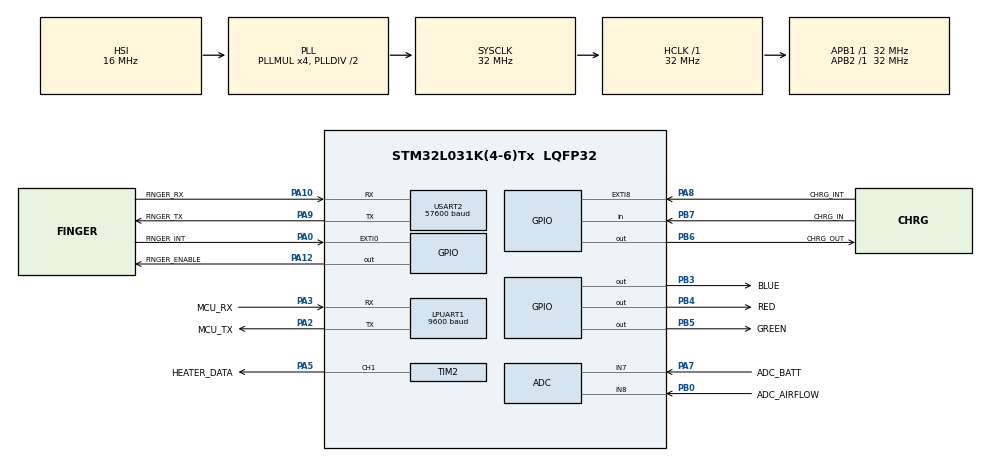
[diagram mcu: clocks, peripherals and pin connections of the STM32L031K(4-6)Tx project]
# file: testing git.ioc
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ADC.ContinuousConvMode=ENABLE
ADC.DMAContinuousRequests=ENABLE
ADC.SamplingTime=ADC_SAMPLETIME_160CYCLES_5
Dma.ADC.3.Direction=DMA_PERIPH_TO_MEMORY
Dma.ADC.3.Instance=DMA1_Channel1
Dma.ADC.3.MemDataAlignment=DMA_MDATAALIGN_WORD
Dma.ADC.3.MemInc=DMA_MINC_ENABLE
Dma.ADC.3.Mode=DMA_CIRCULAR
Dma.ADC.3.PeriphDataAlignment=DMA_PDATAALIGN_WORD
Dma.ADC.3.PeriphInc=DMA_PINC_DISABLE
Dma.ADC.3.Priority=DMA_PRIORITY_LOW
Dma.LPUART1_RX.1.Direction=DMA_PERIPH_TO_MEMORY
Dma.LPUART1_RX.1.Instance=DMA1_Channel3
Dma.LPUART1_RX.1.MemDataAlignment=DMA_MDATAALIGN_BYTE
Dma.LPUART1_RX.1.MemInc=DMA_MINC_ENABLE
Dma.LPUART1_RX.1.Mode=DMA_NORMAL
Dma.LPUART1_RX.1.PeriphDataAlignment=DMA_PDATAALIGN_BYTE
Dma.LPUART1_RX.1.PeriphInc=DMA_PINC_DISABLE
Dma.LPUART1_RX.1.Priority=DMA_PRIORITY_LOW
Dma.LPUART1_TX.2.Direction=DMA_MEMORY_TO_PERIPH
Dma.LPUART1_TX.2.Instance=DMA1_Channel2
Dma.LPUART1_TX.2.MemDataAlignment=DMA_MDATAALIGN_BYTE
Dma.LPUART1_TX.2.MemInc=DMA_MINC_ENABLE
Dma.LPUART1_TX.2.Mode=DMA_NORMAL
Dma.LPUART1_TX.2.PeriphDataAlignment=DMA_PDATAALIGN_BYTE
Dma.LPUART1_TX.2.PeriphInc=DMA_PINC_DISABLE
Dma.LPUART1_TX.2.Priority=DMA_PRIORITY_LOW
Dma.Request0=TIM2_CH1
Dma.Request1=LPUART1_RX
Dma.Request2=LPUART1_TX
Dma.Request3=ADC
Dma.TIM2_CH1.0.Direction=DMA_MEMORY_TO_PERIPH
Dma.TIM2_CH1.0.Instance=DMA1_Channel5
Dma.TIM2_CH1.0.MemDataAlignment=DMA_MDATAALIGN_HALFWORD
Dma.TIM2_CH1.0.MemInc=DMA_MINC_ENABLE
Dma.TIM2_CH1.0.Mode=DMA_CIRCULAR
Dma.TIM2_CH1.0.PeriphDataAlignment=DMA_PDATAALIGN_HALFWORD
Dma.TIM2_CH1.0.PeriphInc=DMA_PINC_DISABLE
Dma.TIM2_CH1.0.Priority=DMA_PRIORITY_HIGH
LPUART1.BaudRate=9600
LPUART1.WordLength=UART_WORDLENGTH_8B
Mcu.Family=STM32L0
Mcu.Name=STM32L031K(4-6)Tx
Mcu.Package=LQFP32
NVIC.ADC1_COMP_IRQn=true\:1\:0\:true\:false\:true\:true\:true\:true
NVIC.DMA1_Channel1_IRQn=true\:0\:0\:false\:false\:true\:false\:true\:true
NVIC.DMA1_Channel2_3_IRQn=true\:0\:0\:false\:false\:true\:false\:true\:true
NVIC.DMA1_Channel4_5_6_7_IRQn=true\:0\:0\:true\:false\:true\:false\:true\:true
NVIC.EXTI0_1_IRQn=true\:3\:0\:true\:false\:true\:true\:true\:true
NVIC.EXTI4_15_IRQn=true\:3\:0\:true\:false\:true\:true\:true\:true
NVIC.LPUART1_IRQn=true\:1\:0\:true\:false\:true\:true\:true\:true
NVIC.TIM2_IRQn=true\:1\:0\:true\:false\:true\:true\:true\:true
PA0-CK_IN.GPIO_Label=FINGER_INT
PA0-CK_IN.Signal=GPXTI0
PA10.GPIO_Label=FINGER_RX
PA10.Mode=Asynchronous
PA10.Signal=USART2_RX
PA12.GPIO_Label=FINGER_ENABLE
PA12.Signal=GPIO_Output
PA13.Mode=Serial_Wire
PA13.Signal=SYS_SWDIO
PA14.Mode=Serial_Wire
PA14.Signal=SYS_SWCLK
PA2.GPIO_Label=MCU_TX
PA2.Mode=Asynchronous
PA2.Signal=LPUART1_TX
PA3.GPIO_Label=MCU_RX
PA3.Mode=Asynchronous
PA3.Signal=LPUART1_RX
PA5.GPIO_Label=HEATER_DATA
PA5.GPIO_PuPd=GPIO_PULLDOWN
PA5.GPIO_Speed=GPIO_SPEED_FREQ_VERY_HIGH
PA5.Signal=S_TIM2_CH1
PA7.GPIO_Label=ADC_BATT
PA7.Mode=IN7
PA7.Signal=ADC_IN7
PA8.GPIO_Label=CHRG_INT
PA8.Signal=GPXTI8
PA9.GPIO_Label=FINGER_TX
PA9.Mode=Asynchronous
PA9.Signal=USART2_TX
PB0.GPIO_Label=ADC_AIRFLOW
PB0.Mode=IN8
PB0.Signal=ADC_IN8
PB3.GPIO_Label=BLUE
PB3.Signal=GPIO_Output
PB4.GPIO_Label=RED
PB4.Signal=GPIO_Output
PB5.GPIO_Label=GREEN
PB5.Signal=GPIO_Output
PB6.GPIO_Label=CHRG_OUT
PB6.Signal=GPIO_Output
PB7.GPIO_Label=CHRG_IN
PB7.Signal=GPIO_Input
ProjectManager.HeapSize=0x200
ProjectManager.StackSize=0x400
ProjectManager.TargetToolchain=STM32CubeIDE
RCC.ADCFreq_Value=16000000
RCC.AHBFreq_Value=32000000
RCC.APB1Freq_Value=32000000
RCC.APB1TimFreq_Value=32000000
RCC.APB2Freq_Value=32000000
RCC.APB2TimFreq_Value=32000000
RCC.HCLKFreq_Value=32000000
RCC.HSE_VALUE=8000000
RCC.HSI16_VALUE=16000000
RCC.HSI_VALUE=16000000
RCC.LSE_VALUE=32768
RCC.MSIClockRange=RCC_MSIRANGE_6
RCC.MSI_VALUE=4194000
RCC.PLLMUL=RCC_PLLMUL_4
RCC.SYSCLKFreq_VALUE=32000000
RCC.SYSCLKSource=RCC_SYSCLKSOURCE_PLLCLK
RCC.VCOOutputFreq_Value=64000000
SH.S_TIM2_CH1.0=TIM2_CH1,PWM Generation1 CH1
TIM2.Channel-PWM\ Generation1\ CH1=TIM_CHANNEL_1
TIM2.Period=40-1
USART2.BaudRate=57600
USART2.VirtualMode-Asynchronous=VM_ASYNC
VP_ADC_Vref_Input.Mode=IN-Vrefint
VP_TIM2_VS_ClockSourceINT.Mode=Internal
board=custom

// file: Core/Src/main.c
/* USER CODE BEGIN Header */
/**
  ******************************************************************************
  * @file           : main.c
  * @brief          : Main program body
  ******************************************************************************
  * @attention
  *
  * Copyright (c) 2024 STMicroelectronics.
  * All rights reserved.
  *
  * This software is licensed under terms that can be found in the LICENSE file
  * in the root directory of this software component.
  * If no LICENSE file comes with this software, it is provided AS-IS.
  *
  ******************************************************************************
  */
/* USER CODE END Header */
#include "main.h"
#include "adc.h"
#include "dma.h"
#include "usart.h"
#include "tim.h"
#include "gpio.h"

void SystemClock_Config(void);

int main(void)
{

  /* MCU Configuration--------------------------------------------------------*/

  /* Reset of all peripherals, Initializes the Flash interface and the Systick. */
  HAL_Init();

  /* Configure the system clock */
  SystemClock_Config();

  /* Initialize all configured peripherals */
  MX_GPIO_Init();
  MX_DMA_Init();
  MX_ADC_Init();
  MX_TIM2_Init();
  MX_LPUART1_UART_Init();
  MX_USART2_UART_Init();

  /* Infinite loop */
  /* USER CODE BEGIN WHILE */
  while (1)
  {
	  // initial commit >> initial commit
	  // edite by github
	  // edited by stm32cubdeide 1
	  // edited by stm32cubdeide 2
	  // edited by stm32cubdeide 3
	  // edited by stm32cubdeide 4
	  // edited by stm32cubdeide 5
	  // edited by stm32cubdeide >> add new feature >> improvement feature
	  // edited by stm32cubdeide 6

	  /* VERSION 2
	   * initial commit 1
	   * initial commit 2
	   * initial commit 3 >> revisi via master >> revisi via version 2
	   * initial commit 4
	   * initial commit >> revisi
	   * initial commit 6
	   * initial commit 7
	   * initial commit 8
	   * initial commit 9
	   * initial commit 10
	   * initial commit 11
	   * initial commit 12
	  /* VERSION 1
	   * initial commit 1
	   * initial commit 2
	   * initial commit 3
	   */
    /* USER CODE END WHILE */

  }
}

void SystemClock_Config(void)
{
  RCC_OscInitTypeDef RCC_OscInitStruct = {0};
  RCC_ClkInitTypeDef RCC_ClkInitStruct = {0};
  RCC_PeriphCLKInitTypeDef PeriphClkInit = {0};

  /** Configure the main internal regulator output voltage
  */
  __HAL_PWR_VOLTAGESCALING_CONFIG(PWR_REGULATOR_VOLTAGE_SCALE1);

  /** Initializes the RCC Oscillators according to the specified parameters
  * in the RCC_OscInitTypeDef structure.
  */
  RCC_OscInitStruct.OscillatorType = RCC_OSCILLATORTYPE_HSI;
  RCC_OscInitStruct.HSIState = RCC_HSI_ON;
  RCC_OscInitStruct.HSICalibrationValue = RCC_HSICALIBRATION_DEFAULT;
  RCC_OscInitStruct.PLL.PLLState = RCC_PLL_ON;
  RCC_OscInitStruct.PLL.PLLSource = RCC_PLLSOURCE_HSI;
  RCC_OscInitStruct.PLL.PLLMUL = RCC_PLLMUL_4;
  RCC_OscInitStruct.PLL.PLLDIV = RCC_PLLDIV_2;
  if (HAL_RCC_OscConfig(&RCC_OscInitStruct) != HAL_OK)
  {
    Error_Handler();
  }

  /** Initializes the CPU, AHB and APB buses clocks
  */
  RCC_ClkInitStruct.ClockType = RCC_CLOCKTYPE_HCLK|RCC_CLOCKTYPE_SYSCLK
                              |RCC_CLOCKTYPE_PCLK1|RCC_CLOCKTYPE_PCLK2;
  RCC_ClkInitStruct.SYSCLKSource = RCC_SYSCLKSOURCE_PLLCLK;
  RCC_ClkInitStruct.AHBCLKDivider = RCC_SYSCLK_DIV1;
  RCC_ClkInitStruct.APB1CLKDivider = RCC_HCLK_DIV1;
  RCC_ClkInitStruct.APB2CLKDivider = RCC_HCLK_DIV1;

  if (HAL_RCC_ClockConfig(&RCC_ClkInitStruct, FLASH_LATENCY_1) != HAL_OK)
  {
    Error_Handler();
  }
  PeriphClkInit.PeriphClockSelection = RCC_PERIPHCLK_USART2|RCC_PERIPHCLK_LPUART1;
  PeriphClkInit.Usart2ClockSelection = RCC_USART2CLKSOURCE_PCLK1;
  PeriphClkInit.Lpuart1ClockSelection = RCC_LPUART1CLKSOURCE_PCLK1;
  if (HAL_RCCEx_PeriphCLKConfig(&PeriphClkInit) != HAL_OK)
  {
    Error_Handler();
  }
}

void Error_Handler(void)
{
  __disable_irq();
  while (1)
  {
  }
}
